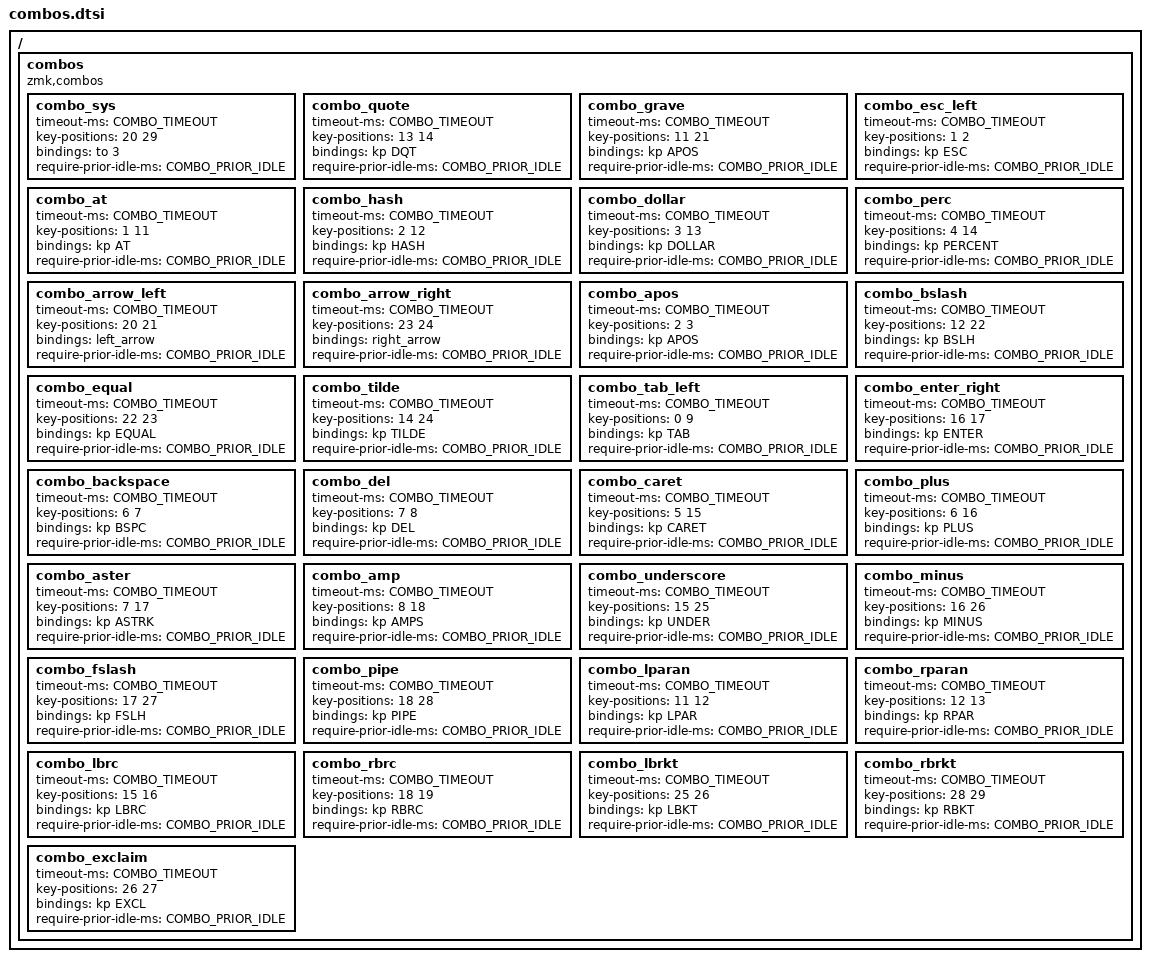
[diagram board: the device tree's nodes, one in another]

#define COMBO_TIMEOUT 50
#define COMBO_PRIOR_IDLE 150

/ {

        combos {
                compatible = "zmk,combos";

                combo_sys {
                    timeout-ms = <COMBO_TIMEOUT>;
                    key-positions = <20 29>;
                    bindings = <&to 3>;
		    require-prior-idle-ms = <COMBO_PRIOR_IDLE>;
                };

		/*
                combo_capword {
                    timeout-ms = <COMBO_TIMEOUT>;
                    key-positions = <31 32>;
                    bindings = <&caps_word>;
		    require-prior-idle-ms = <COMBO_PRIOR_IDLE>;
                };

                combo_numword {
                    timeout-ms = <COMBO_TIMEOUT>;
                    key-positions = <30 33>;
                    bindings = <&num_word>;
		    require-prior-idle-ms = <COMBO_PRIOR_IDLE>;
                };*/

		// 
		// Left hand
		// 

		combo_quote {
                    timeout-ms = <COMBO_TIMEOUT>;
                    key-positions = <13 14>;
                    bindings = <&kp DQT>;
		    require-prior-idle-ms = <COMBO_PRIOR_IDLE>;
                };

		combo_grave {
                    timeout-ms = <COMBO_TIMEOUT>;
                    key-positions = <11 21>;
                    bindings = <&kp APOS>;
		    require-prior-idle-ms = <COMBO_PRIOR_IDLE>;
                };

		combo_esc_left {
                    timeout-ms = <COMBO_TIMEOUT>;
                    key-positions = <1 2>;
                    bindings = <&kp ESC>;
		    require-prior-idle-ms = <COMBO_PRIOR_IDLE>;
                };

		combo_at {
                    timeout-ms = <COMBO_TIMEOUT>;
                    key-positions = <1 11>;
                    bindings = <&kp AT>;
		    require-prior-idle-ms = <COMBO_PRIOR_IDLE>;
                };

		combo_hash {
                    timeout-ms = <COMBO_TIMEOUT>;
                    key-positions = <2 12>;
                    bindings = <&kp HASH>;
		    require-prior-idle-ms = <COMBO_PRIOR_IDLE>;
                };

		combo_dollar {
                    timeout-ms = <COMBO_TIMEOUT>;
                    key-positions = <3 13>;
                    bindings = <&kp DOLLAR>;
		    require-prior-idle-ms = <COMBO_PRIOR_IDLE>;
                };

		combo_perc {
                    timeout-ms = <COMBO_TIMEOUT>;
                    key-positions = <4 14>;
                    bindings = <&kp PERCENT>;
		    require-prior-idle-ms = <COMBO_PRIOR_IDLE>;
                };

		combo_arrow_left {
                    timeout-ms = <COMBO_TIMEOUT>;
                    key-positions = <20 21>;
                    bindings = <&left_arrow>;
		    require-prior-idle-ms = <COMBO_PRIOR_IDLE>;
                };

		combo_arrow_right {
                    timeout-ms = <COMBO_TIMEOUT>;
                    key-positions = <23 24>;
                    bindings = <&right_arrow>;
		    require-prior-idle-ms = <COMBO_PRIOR_IDLE>;
                };

		combo_apos {
                    timeout-ms = <COMBO_TIMEOUT>;
                    key-positions = <2 3>;
                    bindings = <&kp APOS>;
		    require-prior-idle-ms = <COMBO_PRIOR_IDLE>;
                };

		combo_bslash {
                    timeout-ms = <COMBO_TIMEOUT>;
                    key-positions = <12 22>;
                    bindings = <&kp BSLH>;
		    require-prior-idle-ms = <COMBO_PRIOR_IDLE>;
                };

		combo_equal {
                    timeout-ms = <COMBO_TIMEOUT>;
                    key-positions = <22 23>;
                    bindings = <&kp EQUAL>;
		    require-prior-idle-ms = <COMBO_PRIOR_IDLE>;
                };

		combo_tilde {
                    timeout-ms = <COMBO_TIMEOUT>;
                    key-positions = <14 24>;
                    bindings = <&kp TILDE>;
		    require-prior-idle-ms = <COMBO_PRIOR_IDLE>;
                };

		combo_tab_left {
                    timeout-ms = <COMBO_TIMEOUT>;
                    key-positions = <0 9>;
                    bindings = <&kp TAB>;
		    require-prior-idle-ms = <COMBO_PRIOR_IDLE>;
                };

		// 
		// Right hand
		// 

		combo_enter_right {
                    timeout-ms = <COMBO_TIMEOUT>;
                    key-positions = <16 17>;
                    bindings = <&kp ENTER>;
		    require-prior-idle-ms = <COMBO_PRIOR_IDLE>;
                };

                combo_backspace {
                    timeout-ms = <COMBO_TIMEOUT>;
                    key-positions = <6 7>;
                    bindings = <&kp BSPC>;
		    require-prior-idle-ms = <COMBO_PRIOR_IDLE>;
                };

                combo_del {
                    timeout-ms = <COMBO_TIMEOUT>;
                    key-positions = <7 8>;
                    bindings = <&kp DEL>;
		    require-prior-idle-ms = <COMBO_PRIOR_IDLE>;
                };

                combo_caret {
                    timeout-ms = <COMBO_TIMEOUT>;
                    key-positions = <5 15>;
                    bindings = <&kp CARET>;
		    require-prior-idle-ms = <COMBO_PRIOR_IDLE>;
                };

                combo_plus {
                    timeout-ms = <COMBO_TIMEOUT>;
                    key-positions = <6 16>;
                    bindings = <&kp PLUS>;
		    require-prior-idle-ms = <COMBO_PRIOR_IDLE>;
                };

                combo_aster {
                    timeout-ms = <COMBO_TIMEOUT>;
                    key-positions = <7 17>;
                    bindings = <&kp ASTRK>;
		    require-prior-idle-ms = <COMBO_PRIOR_IDLE>;
                };

                combo_amp {
                    timeout-ms = <COMBO_TIMEOUT>;
                    key-positions = <8 18>;
                    bindings = <&kp AMPS>;
		    require-prior-idle-ms = <COMBO_PRIOR_IDLE>;
                };

                combo_underscore {
                    timeout-ms = <COMBO_TIMEOUT>;
                    key-positions = <15 25>;
                    bindings = <&kp UNDER>;
		    require-prior-idle-ms = <COMBO_PRIOR_IDLE>;
                };

                combo_minus {
                    timeout-ms = <COMBO_TIMEOUT>;
                    key-positions = <16 26>;
                    bindings = <&kp MINUS>;
		    require-prior-idle-ms = <COMBO_PRIOR_IDLE>;
                };

                combo_fslash {
                    timeout-ms = <COMBO_TIMEOUT>;
                    key-positions = <17 27>;
                    bindings = <&kp FSLH>;
		    require-prior-idle-ms = <COMBO_PRIOR_IDLE>;
                };

                combo_pipe {
                    timeout-ms = <COMBO_TIMEOUT>;
                    key-positions = <18 28>;
                    bindings = <&kp PIPE>;
		    require-prior-idle-ms = <COMBO_PRIOR_IDLE>;
                };

                combo_lparan {
                    timeout-ms = <COMBO_TIMEOUT>;
                    key-positions = <11 12>;
                    bindings = <&kp LPAR>;
		    require-prior-idle-ms = <COMBO_PRIOR_IDLE>;
                };

                combo_rparan {
                    timeout-ms = <COMBO_TIMEOUT>;
                    key-positions = <12 13>;
                    bindings = <&kp RPAR>;
		    require-prior-idle-ms = <COMBO_PRIOR_IDLE>;
                };

                combo_lbrc {
                    timeout-ms = <COMBO_TIMEOUT>;
                    key-positions = <15 16>;
                    bindings = <&kp LBRC>;
		    require-prior-idle-ms = <COMBO_PRIOR_IDLE>;
                };

                combo_rbrc {
                    timeout-ms = <COMBO_TIMEOUT>;
                    key-positions = <18 19>;
                    bindings = <&kp RBRC>;
		    require-prior-idle-ms = <COMBO_PRIOR_IDLE>;
                };

                combo_lbrkt {
                    timeout-ms = <COMBO_TIMEOUT>;
                    key-positions = <25 26>;
                    bindings = <&kp LBKT>;
		    require-prior-idle-ms = <COMBO_PRIOR_IDLE>;
                };

                combo_rbrkt {
                    timeout-ms = <COMBO_TIMEOUT>;
                    key-positions = <28 29>;
                    bindings = <&kp RBKT>;
		    require-prior-idle-ms = <COMBO_PRIOR_IDLE>;
                };

                combo_exclaim {
                    timeout-ms = <COMBO_TIMEOUT>;
                    key-positions = <26 27>;
                    bindings = <&kp EXCL>;
		    require-prior-idle-ms = <COMBO_PRIOR_IDLE>;
                };

            };

    };
